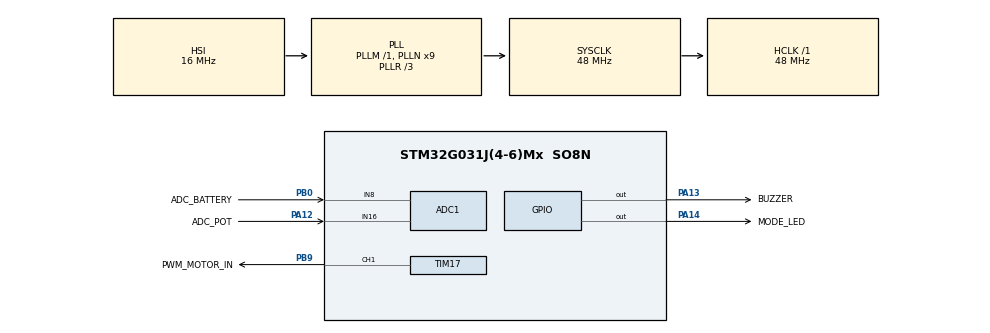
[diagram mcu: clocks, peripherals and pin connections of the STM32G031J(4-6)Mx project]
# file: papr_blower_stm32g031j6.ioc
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ADC1.Channel-0\#ChannelRegularConversion=ADC_CHANNEL_8
ADC1.Channel-1\#ChannelRegularConversion=ADC_CHANNEL_16
ADC1.Channel-2\#ChannelRegularConversion=ADC_CHANNEL_TEMPSENSOR
ADC1.Channel-3\#ChannelRegularConversion=ADC_CHANNEL_VREFINT
ADC1.ClockPrescaler=ADC_CLOCK_SYNC_PCLK_DIV4
ADC1.ContinuousConvMode=ENABLE
ADC1.DMAContinuousRequests=ENABLE
ADC1.EOCSelection=ADC_EOC_SEQ_CONV
ADC1.NbrOfConversion=4
ADC1.NbrOfConversionFlag=1
ADC1.Overrun=ADC_OVR_DATA_OVERWRITTEN
ADC1.OversamplingMode=DISABLE
ADC1.Rank-0\#ChannelRegularConversion=1
ADC1.Rank-1\#ChannelRegularConversion=2
ADC1.Rank-2\#ChannelRegularConversion=3
ADC1.Rank-3\#ChannelRegularConversion=4
ADC1.SamplingTime-0\#ChannelRegularConversion=ADC_SAMPLINGTIME_COMMON_1
ADC1.SamplingTime-1\#ChannelRegularConversion=ADC_SAMPLINGTIME_COMMON_1
ADC1.SamplingTime-2\#ChannelRegularConversion=ADC_SAMPLINGTIME_COMMON_1
ADC1.SamplingTime-3\#ChannelRegularConversion=ADC_SAMPLINGTIME_COMMON_1
ADC1.SamplingTimeCommon1=ADC_SAMPLETIME_160CYCLES_5
ADC1.SamplingTimeCommon2=ADC_SAMPLETIME_160CYCLES_5
ADC1.master=1
Dma.ADC1.0.Direction=DMA_PERIPH_TO_MEMORY
Dma.ADC1.0.EventEnable=DISABLE
Dma.ADC1.0.Instance=DMA1_Channel1
Dma.ADC1.0.MemDataAlignment=DMA_MDATAALIGN_HALFWORD
Dma.ADC1.0.MemInc=DMA_MINC_ENABLE
Dma.ADC1.0.Mode=DMA_CIRCULAR
Dma.ADC1.0.PeriphDataAlignment=DMA_PDATAALIGN_HALFWORD
Dma.ADC1.0.PeriphInc=DMA_PINC_DISABLE
Dma.ADC1.0.Polarity=HAL_DMAMUX_REQ_GEN_RISING
Dma.ADC1.0.Priority=DMA_PRIORITY_LOW
Dma.ADC1.0.RequestNumber=1
Dma.ADC1.0.SignalID=NONE
Dma.ADC1.0.SyncEnable=DISABLE
Dma.ADC1.0.SyncPolarity=HAL_DMAMUX_SYNC_NO_EVENT
Dma.ADC1.0.SyncRequestNumber=1
Dma.ADC1.0.SyncSignalID=NONE
Dma.Request0=ADC1
Mcu.Family=STM32G0
Mcu.Name=STM32G031J(4-6)Mx
Mcu.Package=SO8N
NVIC.DMA1_Channel1_IRQn=true\:0\:0\:false\:false\:true\:false\:true
NVIC.TIM14_IRQn=true\:0\:0\:false\:false\:true\:false\:true
NVIC.TimeBase=TIM14_IRQn
NVIC.TimeBaseIP=TIM14
PA12\ [PA10].GPIO_Label=ADC_POT
PA12\ [PA10].Mode=IN16
PA12\ [PA10].Signal=ADC1_IN16
PA13.GPIO_Label=BUZZER
PA13.Signal=GPIO_Output
PA14-BOOT0.GPIO_Label=MODE_LED
PA14-BOOT0.Signal=GPIO_Output
PB0.GPIO_Label=ADC_BATTERY
PB0.Mode=IN8
PB0.Signal=ADC1_IN8
PB9.GPIO_Label=PWM_MOTOR_IN
PB9.Signal=S_TIM17_CH1
ProjectManager.HeapSize=0x200
ProjectManager.StackSize=0x400
ProjectManager.TargetToolchain=Other Toolchains (GPDSC)
RCC.ADCFreq_Value=48000000
RCC.AHBFreq_Value=48000000
RCC.CortexFreq_Value=48000000
RCC.EXTERNAL_CLOCK_VALUE=12288000
RCC.HCLKFreq_Value=48000000
RCC.HSE_VALUE=8000000
RCC.HSISYSCLKDivider=RCC_HSI_DIV8
RCC.HSI_VALUE=16000000
RCC.LSE_VALUE=32768
RCC.PLLN=9
RCC.PLLR=RCC_PLLR_DIV3
RCC.SYSCLKFreq_VALUE=48000000
RCC.SYSCLKSource=RCC_SYSCLKSOURCE_PLLCLK
RCC.VCOOutputFreq_Value=144000000
SH.S_TIM17_CH1.0=TIM17_CH1,PWM Generation1 CH1
TIM17.Channel=TIM_CHANNEL_1
VP_ADC1_TempSens_Input.Mode=IN-TempSens
VP_ADC1_Vref_Input.Mode=IN-Vrefint
VP_SYS_VS_tim14.Mode=TIM14
VP_TIM17_VS_ClockSourceINT.Mode=Enable_Timer
board=STM32G0316-DISCO

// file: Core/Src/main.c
/* USER CODE BEGIN Header */
/**
  ******************************************************************************
  * @file           : main.c
  * @brief          : Main program body
  ******************************************************************************
  * @attention
  *
  * <h2><center>&copy; Copyright (c) 2020 STMicroelectronics.
  * All rights reserved.</center></h2>
  *
  * This software component is licensed by ST under BSD 3-Clause license,
  * the "License"; You may not use this file except in compliance with the
  * License. You may obtain a copy of the License at:
  *                        opensource.org/licenses/BSD-3-Clause
  *
  ******************************************************************************
  */
/* USER CODE END Header */

#include "main.h"

/* USER CODE BEGIN Includes */
#include "applicationInterface.h"
/* USER CODE END Includes */

ADC_HandleTypeDef hadc1;
DMA_HandleTypeDef hdma_adc1;

TIM_HandleTypeDef htim17;

void SystemClock_Config(void);
static void MX_GPIO_Init(void);
static void MX_DMA_Init(void);
static void MX_ADC1_Init(void);
static void MX_TIM17_Init(void);

int main(void)
{

  /* MCU Configuration--------------------------------------------------------*/

  /* Reset of all peripherals, Initializes the Flash interface and the Systick. */
  HAL_Init();

  /* Configure the system clock */
  SystemClock_Config();

  /* Initialize all configured peripherals */
  MX_GPIO_Init();
  MX_DMA_Init();
  MX_ADC1_Init();
  MX_TIM17_Init();
  /* USER CODE BEGIN 2 */
  applicationLoop();
  applicationSetup();
  /* USER CODE END 2 */

  /* Infinite loop */
  while (1)
  {

  }
}

void SystemClock_Config(void)
{
  RCC_OscInitTypeDef RCC_OscInitStruct = {0};
  RCC_ClkInitTypeDef RCC_ClkInitStruct = {0};
  RCC_PeriphCLKInitTypeDef PeriphClkInit = {0};

  /** Configure the main internal regulator output voltage
  */
  HAL_PWREx_ControlVoltageScaling(PWR_REGULATOR_VOLTAGE_SCALE1);
  /** Initializes the CPU, AHB and APB busses clocks
  */
  RCC_OscInitStruct.OscillatorType = RCC_OSCILLATORTYPE_HSI;
  RCC_OscInitStruct.HSIState = RCC_HSI_ON;
  RCC_OscInitStruct.HSIDiv = RCC_HSI_DIV8;
  RCC_OscInitStruct.HSICalibrationValue = RCC_HSICALIBRATION_DEFAULT;
  RCC_OscInitStruct.PLL.PLLState = RCC_PLL_ON;
  RCC_OscInitStruct.PLL.PLLSource = RCC_PLLSOURCE_HSI;
  RCC_OscInitStruct.PLL.PLLM = RCC_PLLM_DIV1;
  RCC_OscInitStruct.PLL.PLLN = 9;
  RCC_OscInitStruct.PLL.PLLP = RCC_PLLP_DIV2;
  RCC_OscInitStruct.PLL.PLLQ = RCC_PLLQ_DIV2;
  RCC_OscInitStruct.PLL.PLLR = RCC_PLLR_DIV3;
  if (HAL_RCC_OscConfig(&RCC_OscInitStruct) != HAL_OK)
  {
    Error_Handler();
  }
  /** Initializes the CPU, AHB and APB busses clocks
  */
  RCC_ClkInitStruct.ClockType = RCC_CLOCKTYPE_HCLK|RCC_CLOCKTYPE_SYSCLK
                              |RCC_CLOCKTYPE_PCLK1;
  RCC_ClkInitStruct.SYSCLKSource = RCC_SYSCLKSOURCE_PLLCLK;
  RCC_ClkInitStruct.AHBCLKDivider = RCC_SYSCLK_DIV1;
  RCC_ClkInitStruct.APB1CLKDivider = RCC_HCLK_DIV1;

  if (HAL_RCC_ClockConfig(&RCC_ClkInitStruct, FLASH_LATENCY_1) != HAL_OK)
  {
    Error_Handler();
  }
  /** Initializes the peripherals clocks
  */
  PeriphClkInit.PeriphClockSelection = RCC_PERIPHCLK_ADC;
  PeriphClkInit.AdcClockSelection = RCC_ADCCLKSOURCE_SYSCLK;
  if (HAL_RCCEx_PeriphCLKConfig(&PeriphClkInit) != HAL_OK)
  {
    Error_Handler();
  }
}

static void MX_ADC1_Init(void)
{

  ADC_AnalogWDGConfTypeDef AnalogWDGConfig = {0};
  ADC_ChannelConfTypeDef sConfig = {0};

  /** Configure the global features of the ADC (Clock, Resolution, Data Alignment and number of conversion)
  */
  hadc1.Instance = ADC1;
  hadc1.Init.ClockPrescaler = ADC_CLOCK_SYNC_PCLK_DIV4;
  hadc1.Init.Resolution = ADC_RESOLUTION_12B;
  hadc1.Init.DataAlign = ADC_DATAALIGN_RIGHT;
  hadc1.Init.ScanConvMode = ADC_SCAN_ENABLE;
  hadc1.Init.EOCSelection = ADC_EOC_SEQ_CONV;
  hadc1.Init.LowPowerAutoWait = DISABLE;
  hadc1.Init.LowPowerAutoPowerOff = DISABLE;
  hadc1.Init.ContinuousConvMode = ENABLE;
  hadc1.Init.NbrOfConversion = 4;
  hadc1.Init.DiscontinuousConvMode = DISABLE;
  hadc1.Init.ExternalTrigConv = ADC_SOFTWARE_START;
  hadc1.Init.ExternalTrigConvEdge = ADC_EXTERNALTRIGCONVEDGE_NONE;
  hadc1.Init.DMAContinuousRequests = ENABLE;
  hadc1.Init.Overrun = ADC_OVR_DATA_OVERWRITTEN;
  hadc1.Init.SamplingTimeCommon1 = ADC_SAMPLETIME_160CYCLES_5;
  hadc1.Init.SamplingTimeCommon2 = ADC_SAMPLETIME_160CYCLES_5;
  hadc1.Init.OversamplingMode = DISABLE;
  hadc1.Init.TriggerFrequencyMode = ADC_TRIGGER_FREQ_HIGH;
  if (HAL_ADC_Init(&hadc1) != HAL_OK)
  {
    Error_Handler();
  }
  /** Configure Analog WatchDog 2
  */
  AnalogWDGConfig.WatchdogMode = ADC_ANALOGWATCHDOG_SINGLE_REG;
  if (HAL_ADC_AnalogWDGConfig(&hadc1, &AnalogWDGConfig) != HAL_OK)
  {
    Error_Handler();
  }
  /** Configure Regular Channel
  */
  sConfig.Channel = ADC_CHANNEL_8;
  sConfig.Rank = ADC_REGULAR_RANK_1;
  sConfig.SamplingTime = ADC_SAMPLINGTIME_COMMON_1;
  if (HAL_ADC_ConfigChannel(&hadc1, &sConfig) != HAL_OK)
  {
    Error_Handler();
  }
  /** Configure Regular Channel
  */
  sConfig.Channel = ADC_CHANNEL_16;
  sConfig.Rank = ADC_REGULAR_RANK_2;
  if (HAL_ADC_ConfigChannel(&hadc1, &sConfig) != HAL_OK)
  {
    Error_Handler();
  }
  /** Configure Regular Channel
  */
  sConfig.Channel = ADC_CHANNEL_TEMPSENSOR;
  sConfig.Rank = ADC_REGULAR_RANK_3;
  if (HAL_ADC_ConfigChannel(&hadc1, &sConfig) != HAL_OK)
  {
    Error_Handler();
  }
  /** Configure Regular Channel
  */
  sConfig.Channel = ADC_CHANNEL_VREFINT;
  sConfig.Rank = ADC_REGULAR_RANK_4;
  if (HAL_ADC_ConfigChannel(&hadc1, &sConfig) != HAL_OK)
  {
    Error_Handler();
  }

}

static void MX_TIM17_Init(void)
{

  TIM_OC_InitTypeDef sConfigOC = {0};
  TIM_BreakDeadTimeConfigTypeDef sBreakDeadTimeConfig = {0};

  htim17.Instance = TIM17;
  htim17.Init.Prescaler = 0;
  htim17.Init.CounterMode = TIM_COUNTERMODE_UP;
  htim17.Init.Period = 0;
  htim17.Init.ClockDivision = TIM_CLOCKDIVISION_DIV1;
  htim17.Init.RepetitionCounter = 0;
  htim17.Init.AutoReloadPreload = TIM_AUTORELOAD_PRELOAD_DISABLE;
  if (HAL_TIM_Base_Init(&htim17) != HAL_OK)
  {
    Error_Handler();
  }
  if (HAL_TIM_PWM_Init(&htim17) != HAL_OK)
  {
    Error_Handler();
  }
  sConfigOC.OCMode = TIM_OCMODE_PWM1;
  sConfigOC.Pulse = 0;
  sConfigOC.OCPolarity = TIM_OCPOLARITY_HIGH;
  sConfigOC.OCNPolarity = TIM_OCNPOLARITY_HIGH;
  sConfigOC.OCFastMode = TIM_OCFAST_DISABLE;
  sConfigOC.OCIdleState = TIM_OCIDLESTATE_RESET;
  sConfigOC.OCNIdleState = TIM_OCNIDLESTATE_RESET;
  if (HAL_TIM_PWM_ConfigChannel(&htim17, &sConfigOC, TIM_CHANNEL_1) != HAL_OK)
  {
    Error_Handler();
  }
  sBreakDeadTimeConfig.OffStateRunMode = TIM_OSSR_DISABLE;
  sBreakDeadTimeConfig.OffStateIDLEMode = TIM_OSSI_DISABLE;
  sBreakDeadTimeConfig.LockLevel = TIM_LOCKLEVEL_OFF;
  sBreakDeadTimeConfig.DeadTime = 0;
  sBreakDeadTimeConfig.BreakState = TIM_BREAK_DISABLE;
  sBreakDeadTimeConfig.BreakPolarity = TIM_BREAKPOLARITY_HIGH;
  sBreakDeadTimeConfig.BreakFilter = 0;
  sBreakDeadTimeConfig.AutomaticOutput = TIM_AUTOMATICOUTPUT_DISABLE;
  if (HAL_TIMEx_ConfigBreakDeadTime(&htim17, &sBreakDeadTimeConfig) != HAL_OK)
  {
    Error_Handler();
  }
  HAL_TIM_MspPostInit(&htim17);

}

static void MX_DMA_Init(void)
{

  /* DMA controller clock enable */
  __HAL_RCC_DMA1_CLK_ENABLE();

  /* DMA interrupt init */
  /* DMA1_Channel1_IRQn interrupt configuration */
  HAL_NVIC_SetPriority(DMA1_Channel1_IRQn, 0, 0);
  HAL_NVIC_EnableIRQ(DMA1_Channel1_IRQn);

}

static void MX_GPIO_Init(void)
{
  GPIO_InitTypeDef GPIO_InitStruct = {0};

  /* GPIO Ports Clock Enable */
  __HAL_RCC_GPIOB_CLK_ENABLE();
  __HAL_RCC_GPIOA_CLK_ENABLE();

  /*Configure GPIO pin Output Level */
  HAL_GPIO_WritePin(GPIOA, BUZZER_Pin|MODE_LED_Pin, GPIO_PIN_RESET);

  /*Configure GPIO pins : BUZZER_Pin MODE_LED_Pin */
  GPIO_InitStruct.Pin = BUZZER_Pin|MODE_LED_Pin;
  GPIO_InitStruct.Mode = GPIO_MODE_OUTPUT_PP;
  GPIO_InitStruct.Pull = GPIO_NOPULL;
  GPIO_InitStruct.Speed = GPIO_SPEED_FREQ_LOW;
  HAL_GPIO_Init(GPIOA, &GPIO_InitStruct);

}

 /**
  * @brief  Period elapsed callback in non blocking mode
  * @note   This function is called  when TIM14 interrupt took place, inside
  * HAL_TIM_IRQHandler(). It makes a direct call to HAL_IncTick() to increment
  * a global variable "uwTick" used as application time base.
  * @param  htim : TIM handle
  * @retval None
  */
void HAL_TIM_PeriodElapsedCallback(TIM_HandleTypeDef *htim)
{
  if (htim->Instance == TIM14) {
    HAL_IncTick();
  }
}

void Error_Handler(void)
{
}

/************************ (C) COPYRIGHT STMicroelectronics *****END OF FILE****/
